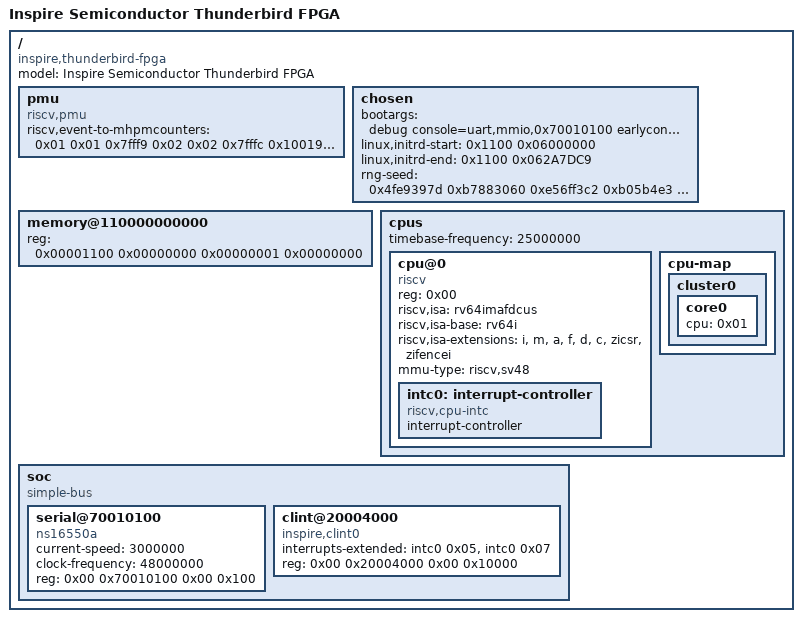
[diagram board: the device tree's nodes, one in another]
/dts-v1/;

/ {
	#address-cells = <0x02>;
	#size-cells = <0x02>;
	compatible = "inspire,thunderbird-fpga", "inspire,thunderbird";
	model = "Inspire Semiconductor Thunderbird FPGA";

	pmu {
		riscv,event-to-mhpmcounters = <0x01 0x01 0x7fff9 0x02 0x02 0x7fffc 0x10019 0x10019 0x7fff8 0x1001b 0x1001b 0x7fff8 0x10021 0x10021 0x7fff8>;
		compatible = "riscv,pmu";
	};

 	chosen {
		bootargs = "debug console=uart,mmio,0x70010100 earlycon=uart,mmio,0x70010100 rodata=on no5lvl";
		linux,initrd-start = <0x1100 0x06000000>;
		linux,initrd-end = <0x1100 0x062A7DC9>;
		rng-seed = <0x4fe9397d 0xb7883060 0xe56ff3c2 0xb05b4e3 0x62e5479c 0xd932a9c8 0x95a47b5b 0x192ef245>;
        };

	memory@110000000000 {
		device_type = "memory";
		reg = <0x00001100 0x00000000 0x00000001 0x00000000>;
	};

	cpus {
		#address-cells = <0x01>;
		#size-cells = <0x00>;
		timebase-frequency = <25000000>;

		cpu@0 {
			phandle = <0x01>;
			device_type = "cpu";
			reg = <0x00>;
			status = "okay";
			compatible = "riscv";
			riscv,isa = "rv64imafdcus";
			riscv,isa-base = "rv64i";
			riscv,isa-extensions = "i", "m", "a", "f", "d", "c", "zicsr", "zifencei" ;
			mmu-type = "riscv,sv48";
			intc0: interrupt-controller {
				#interrupt-cells = <0x01>;
				interrupt-controller;
				compatible = "riscv,cpu-intc";
				phandle = <0x02>;
			};
		};

		cpu-map {

			cluster0 {

				core0 {
					cpu = <0x01>;
				};
			};
		};
	};

	soc {
		#address-cells = <0x02>;
		#size-cells = <0x02>;
		compatible = "simple-bus";
		ranges;

		serial@70010100 {
			current-speed = <3000000>;
			clock-frequency = <48000000>;
			reg = <0x00 0x70010100 0x00 0x100>;
			compatible = "ns16550a";
		};

		clint@20004000 {
			interrupts-extended = <&intc0 0x05 &intc0 0x07>;
			reg = <0x00 0x20004000 0x00 0x10000>;
			compatible = "inspire,clint0";
		};
	};
};
